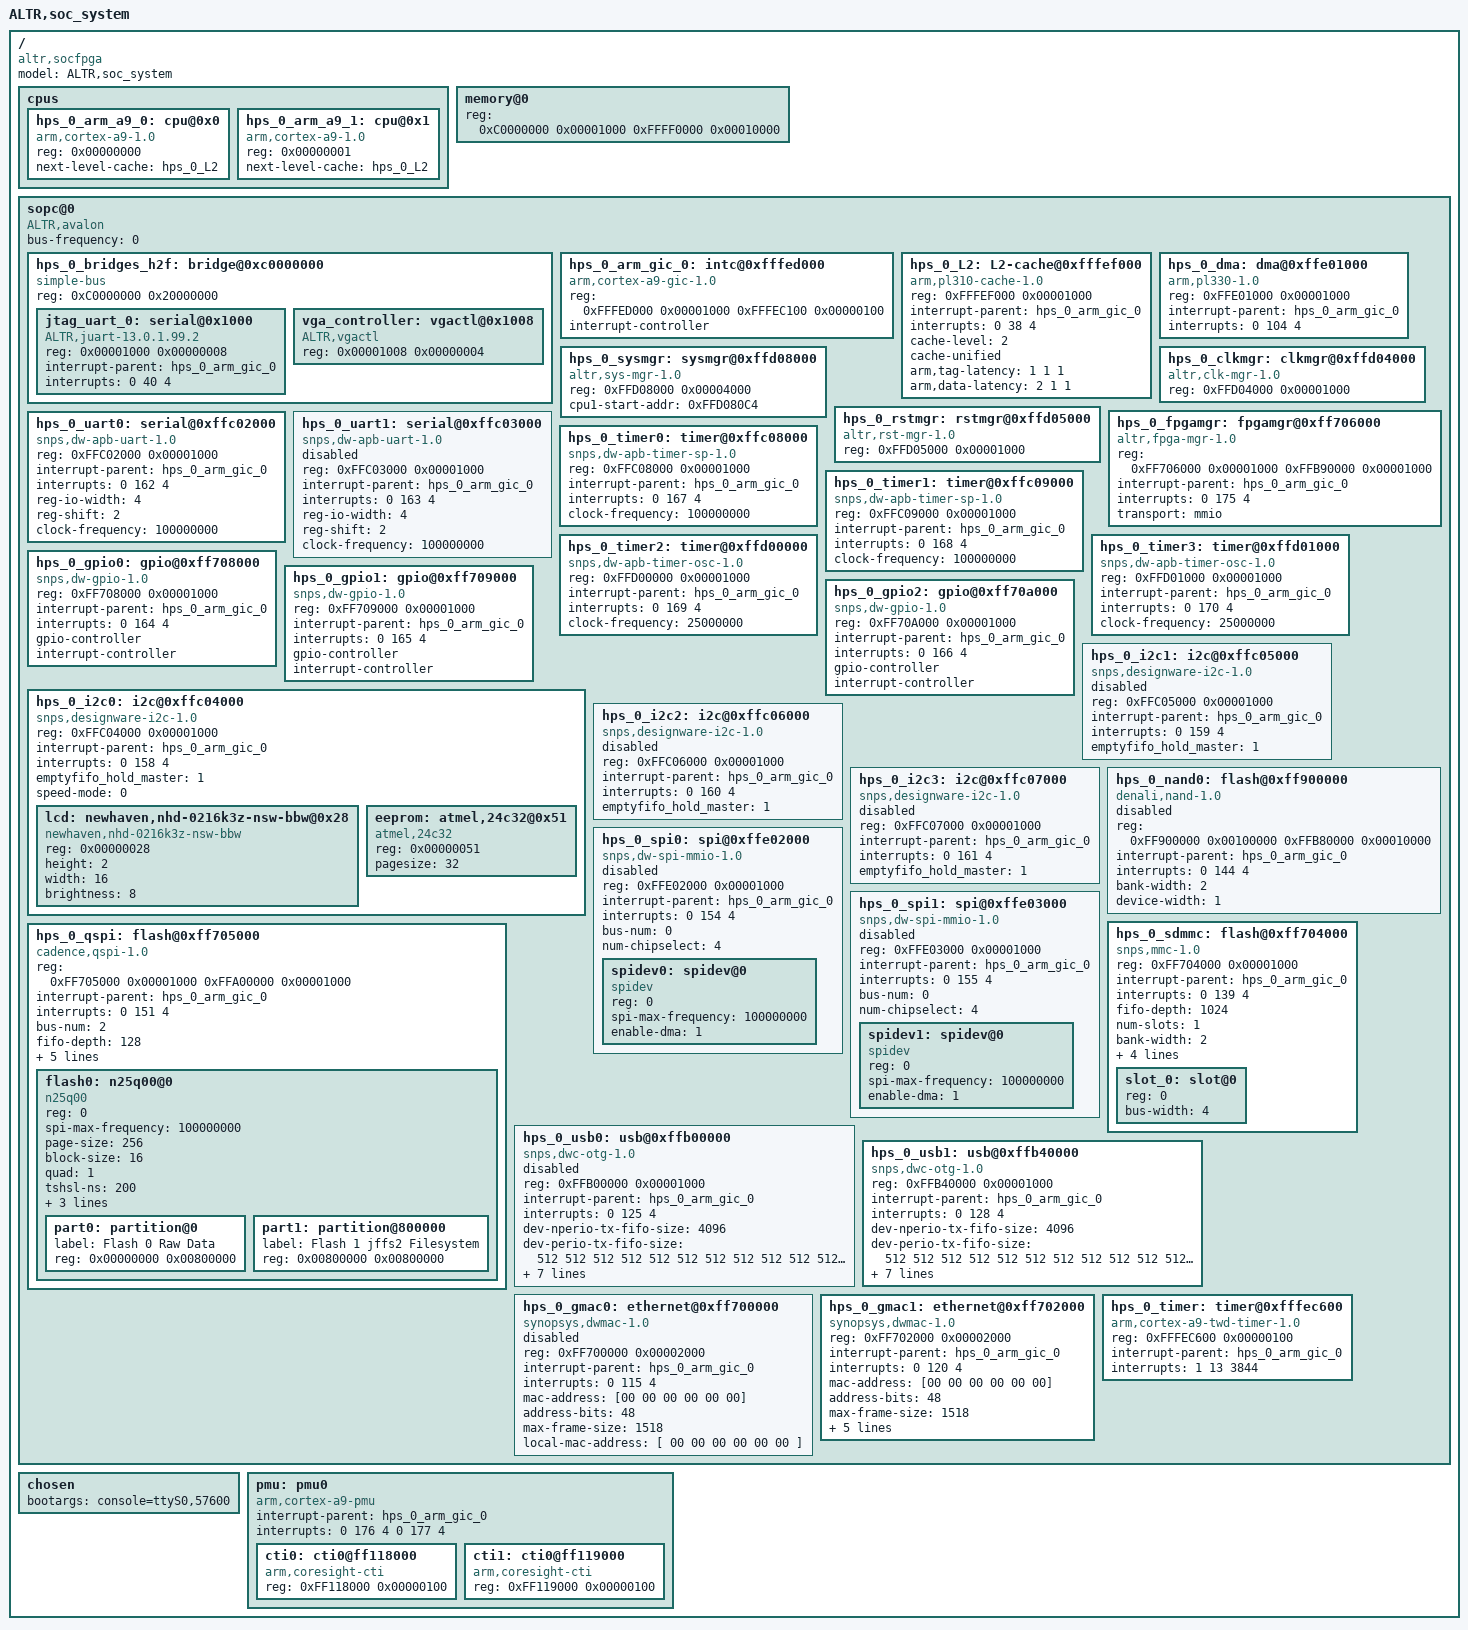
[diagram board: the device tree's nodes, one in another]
/*
 * This devicetree is generated by sopc2dts on Thu Dec 05 01:38:15 EST 2013
 * Sopc2dts is written by Walter Goossens <waltergoossens@home.nl>
 * in cooperation with the nios2 community <Nios2-dev@sopc.et.ntust.edu.tw>
 */
/dts-v1/;

/ {
	model = "ALTR,soc_system";
	#address-cells = < 1 >;
	#size-cells = < 1 >;
	compatible = "altr,socfpga";

	cpus {
		#address-cells = < 1 >;
		#size-cells = < 0 >;

		hps_0_arm_a9_0: cpu@0x0 {
			device_type = "cpu";
			compatible = "arm,cortex-a9-1.0", "arm,cortex-a9";
			reg = < 0x00000000 >;
			next-level-cache = < &hps_0_L2 >;	/* appended from boardinfo */
		}; //end cpu@0x0 (hps_0_arm_a9_0)

		hps_0_arm_a9_1: cpu@0x1 {
			device_type = "cpu";
			compatible = "arm,cortex-a9-1.0", "arm,cortex-a9";
			reg = < 0x00000001 >;
			next-level-cache = < &hps_0_L2 >;	/* appended from boardinfo */
		}; //end cpu@0x1 (hps_0_arm_a9_1)
	}; //end cpus

	memory@0 {
		device_type = "memory";
		reg = < 0xC0000000 0x00001000 
			0xFFFF0000 0x00010000 >;
	}; //end memory@0

	sopc@0 {
		device_type = "soc";
		ranges;
		#address-cells = < 1 >;
		#size-cells = < 1 >;
		compatible = "ALTR,avalon", "simple-bus";
		bus-frequency = < 0 >;

		hps_0_bridges_h2f: bridge@0xc0000000 {
			reg = < 0xC0000000 0x20000000 >;
			#address-cells = < 1 >;
			#size-cells = < 1 >;
			ranges = < 0x00000000 0xC0000000 0x00001000 
				0x00001000 0xC0001000 0x00000008 
				0x00001008 0xC0001008 0x00000004 >;
			compatible = "simple-bus";	/* appended from boardinfo */

			jtag_uart_0: serial@0x1000 {
				compatible = "ALTR,juart-13.0.1.99.2", "ALTR,juart-1.0";
				reg = < 0x00001000 0x00000008 >;
				interrupt-parent = < &hps_0_arm_gic_0 >;
				interrupts = < 0 40 4 >;
			}; //end serial@0x1000 (jtag_uart_0)

			vga_controller: vgactl@0x1008 {
				compatible = "ALTR,vgactl", "altr,vgactl";
				reg = < 0x00001008 0x00000004 >;
			}; //end vgactl@0x1008 (vga_controller)
		}; //end bridge@0xc0000000 (hps_0_bridges_h2f)

		hps_0_arm_gic_0: intc@0xfffed000 {
			compatible = "arm,cortex-a9-gic-1.0", "arm,cortex-a9-gic";
			reg = < 0xFFFED000 0x00001000 
				0xFFFEC100 0x00000100 >;
			interrupt-controller;
			#interrupt-cells = < 3 >;
		}; //end intc@0xfffed000 (hps_0_arm_gic_0)

		hps_0_L2: L2-cache@0xfffef000 {
			compatible = "arm,pl310-cache-1.0", "arm,pl310-cache";
			reg = < 0xFFFEF000 0x00001000 >;
			interrupt-parent = < &hps_0_arm_gic_0 >;
			interrupts = < 0 38 4 >;
			cache-level = < 2 >;	/* embeddedsw.dts.params.cache-level type NUMBER */
			cache-unified;	/* appended from boardinfo */
			arm,tag-latency = < 1 1 1 >;	/* appended from boardinfo */
			arm,data-latency = < 2 1 1 >;	/* appended from boardinfo */
		}; //end L2-cache@0xfffef000 (hps_0_L2)

		hps_0_dma: dma@0xffe01000 {
			compatible = "arm,pl330-1.0", "arm,pl330", "arm,primecell";
			reg = < 0xFFE01000 0x00001000 >;
			interrupt-parent = < &hps_0_arm_gic_0 >;
			interrupts = < 0 104 4 >;
		}; //end dma@0xffe01000 (hps_0_dma)

		hps_0_sysmgr: sysmgr@0xffd08000 {
			compatible = "altr,sys-mgr-1.0", "altr,sys-mgr";
			reg = < 0xFFD08000 0x00004000 >;
			cpu1-start-addr = < 0xFFD080C4 >;	/* appended from boardinfo */
		}; //end sysmgr@0xffd08000 (hps_0_sysmgr)

		hps_0_clkmgr: clkmgr@0xffd04000 {
			compatible = "altr,clk-mgr-1.0", "altr,clk-mgr";
			reg = < 0xFFD04000 0x00001000 >;
		}; //end clkmgr@0xffd04000 (hps_0_clkmgr)

		hps_0_rstmgr: rstmgr@0xffd05000 {
			compatible = "altr,rst-mgr-1.0", "altr,rst-mgr";
			reg = < 0xFFD05000 0x00001000 >;
		}; //end rstmgr@0xffd05000 (hps_0_rstmgr)

		hps_0_fpgamgr: fpgamgr@0xff706000 {
			compatible = "altr,fpga-mgr-1.0", "altr,fpga-mgr";
			reg = < 0xFF706000 0x00001000 
				0xFFB90000 0x00001000 >;
			interrupt-parent = < &hps_0_arm_gic_0 >;
			interrupts = < 0 175 4 >;
			transport = "mmio";	/* embeddedsw.dts.params.transport type STRING */
		}; //end fpgamgr@0xff706000 (hps_0_fpgamgr)

		hps_0_uart0: serial@0xffc02000 {
			compatible = "snps,dw-apb-uart-1.0", "snps,dw-apb-uart";
			reg = < 0xFFC02000 0x00001000 >;
			interrupt-parent = < &hps_0_arm_gic_0 >;
			interrupts = < 0 162 4 >;
			reg-io-width = < 4 >;	/* embeddedsw.dts.params.reg-io-width type NUMBER */
			reg-shift = < 2 >;	/* embeddedsw.dts.params.reg-shift type NUMBER */
			clock-frequency = < 100000000 >;	/* appended from boardinfo */
		}; //end serial@0xffc02000 (hps_0_uart0)

		hps_0_uart1: serial@0xffc03000 {
			compatible = "snps,dw-apb-uart-1.0", "snps,dw-apb-uart";
			reg = < 0xFFC03000 0x00001000 >;
			interrupt-parent = < &hps_0_arm_gic_0 >;
			interrupts = < 0 163 4 >;
			reg-io-width = < 4 >;	/* embeddedsw.dts.params.reg-io-width type NUMBER */
			reg-shift = < 2 >;	/* embeddedsw.dts.params.reg-shift type NUMBER */
			clock-frequency = < 100000000 >;	/* appended from boardinfo */
			status = "disabled";	/* appended from boardinfo */
		}; //end serial@0xffc03000 (hps_0_uart1)

		hps_0_timer0: timer@0xffc08000 {
			compatible = "snps,dw-apb-timer-sp-1.0", "snps,dw-apb-timer-sp";
			reg = < 0xFFC08000 0x00001000 >;
			interrupt-parent = < &hps_0_arm_gic_0 >;
			interrupts = < 0 167 4 >;
			clock-frequency = < 100000000 >;	/* appended from boardinfo */
		}; //end timer@0xffc08000 (hps_0_timer0)

		hps_0_timer1: timer@0xffc09000 {
			compatible = "snps,dw-apb-timer-sp-1.0", "snps,dw-apb-timer-sp";
			reg = < 0xFFC09000 0x00001000 >;
			interrupt-parent = < &hps_0_arm_gic_0 >;
			interrupts = < 0 168 4 >;
			clock-frequency = < 100000000 >;	/* appended from boardinfo */
		}; //end timer@0xffc09000 (hps_0_timer1)

		hps_0_timer2: timer@0xffd00000 {
			compatible = "snps,dw-apb-timer-osc-1.0", "snps,dw-apb-timer-osc";
			reg = < 0xFFD00000 0x00001000 >;
			interrupt-parent = < &hps_0_arm_gic_0 >;
			interrupts = < 0 169 4 >;
			clock-frequency = < 25000000 >;	/* appended from boardinfo */
		}; //end timer@0xffd00000 (hps_0_timer2)

		hps_0_timer3: timer@0xffd01000 {
			compatible = "snps,dw-apb-timer-osc-1.0", "snps,dw-apb-timer-osc";
			reg = < 0xFFD01000 0x00001000 >;
			interrupt-parent = < &hps_0_arm_gic_0 >;
			interrupts = < 0 170 4 >;
			clock-frequency = < 25000000 >;	/* appended from boardinfo */
		}; //end timer@0xffd01000 (hps_0_timer3)

		hps_0_gpio0: gpio@0xff708000 {
			compatible = "snps,dw-gpio-1.0", "snps,dw-gpio";
			reg = < 0xFF708000 0x00001000 >;
			interrupt-parent = < &hps_0_arm_gic_0 >;
			interrupts = < 0 164 4 >;
			#gpio-cells = < 2 >;
			gpio-controller;
			interrupt-controller;	/* appended from boardinfo */
			#interrupt-cells = < 2 >;	/* appended from boardinfo */
		}; //end gpio@0xff708000 (hps_0_gpio0)

		hps_0_gpio1: gpio@0xff709000 {
			compatible = "snps,dw-gpio-1.0", "snps,dw-gpio";
			reg = < 0xFF709000 0x00001000 >;
			interrupt-parent = < &hps_0_arm_gic_0 >;
			interrupts = < 0 165 4 >;
			#gpio-cells = < 2 >;
			gpio-controller;
			interrupt-controller;	/* appended from boardinfo */
			#interrupt-cells = < 2 >;	/* appended from boardinfo */
		}; //end gpio@0xff709000 (hps_0_gpio1)

		hps_0_gpio2: gpio@0xff70a000 {
			compatible = "snps,dw-gpio-1.0", "snps,dw-gpio";
			reg = < 0xFF70A000 0x00001000 >;
			interrupt-parent = < &hps_0_arm_gic_0 >;
			interrupts = < 0 166 4 >;
			#gpio-cells = < 2 >;
			gpio-controller;
			interrupt-controller;	/* appended from boardinfo */
			#interrupt-cells = < 2 >;	/* appended from boardinfo */
		}; //end gpio@0xff70a000 (hps_0_gpio2)

		hps_0_i2c0: i2c@0xffc04000 {
			compatible = "snps,designware-i2c-1.0", "snps,designware-i2c";
			reg = < 0xFFC04000 0x00001000 >;
			interrupt-parent = < &hps_0_arm_gic_0 >;
			interrupts = < 0 158 4 >;
			emptyfifo_hold_master = < 1 >;	/* embeddedsw.dts.params.emptyfifo_hold_master type NUMBER */
			#address-cells = < 1 >;
			#size-cells = < 0 >;
			speed-mode = < 0 >;	/* appended from boardinfo */

			lcd: newhaven,nhd-0216k3z-nsw-bbw@0x28 {
				compatible = "newhaven,nhd-0216k3z-nsw-bbw";
				reg = < 0x00000028 >;
				height = < 2 >;	/* appended from boardinfo */
				width = < 16 >;	/* appended from boardinfo */
				brightness = < 8 >;	/* appended from boardinfo */
			}; //end newhaven,nhd-0216k3z-nsw-bbw@0x28 (lcd)

			eeprom: atmel,24c32@0x51 {
				compatible = "atmel,24c32";
				reg = < 0x00000051 >;
				pagesize = < 32 >;	/* appended from boardinfo */
			}; //end atmel,24c32@0x51 (eeprom)
		}; //end i2c@0xffc04000 (hps_0_i2c0)

		hps_0_i2c1: i2c@0xffc05000 {
			compatible = "snps,designware-i2c-1.0", "snps,designware-i2c";
			reg = < 0xFFC05000 0x00001000 >;
			interrupt-parent = < &hps_0_arm_gic_0 >;
			interrupts = < 0 159 4 >;
			emptyfifo_hold_master = < 1 >;	/* embeddedsw.dts.params.emptyfifo_hold_master type NUMBER */
			status = "disabled";	/* appended from boardinfo */
		}; //end i2c@0xffc05000 (hps_0_i2c1)

		hps_0_i2c2: i2c@0xffc06000 {
			compatible = "snps,designware-i2c-1.0", "snps,designware-i2c";
			reg = < 0xFFC06000 0x00001000 >;
			interrupt-parent = < &hps_0_arm_gic_0 >;
			interrupts = < 0 160 4 >;
			emptyfifo_hold_master = < 1 >;	/* embeddedsw.dts.params.emptyfifo_hold_master type NUMBER */
			status = "disabled";	/* appended from boardinfo */
		}; //end i2c@0xffc06000 (hps_0_i2c2)

		hps_0_i2c3: i2c@0xffc07000 {
			compatible = "snps,designware-i2c-1.0", "snps,designware-i2c";
			reg = < 0xFFC07000 0x00001000 >;
			interrupt-parent = < &hps_0_arm_gic_0 >;
			interrupts = < 0 161 4 >;
			emptyfifo_hold_master = < 1 >;	/* embeddedsw.dts.params.emptyfifo_hold_master type NUMBER */
			status = "disabled";	/* appended from boardinfo */
		}; //end i2c@0xffc07000 (hps_0_i2c3)

		hps_0_nand0: flash@0xff900000 {
			compatible = "denali,nand-1.0", "denali,denali-nand-dt";
			reg = < 0xFF900000 0x00100000 
				0xFFB80000 0x00010000 >;
			interrupt-parent = < &hps_0_arm_gic_0 >;
			interrupts = < 0 144 4 >;
			#adress-cells = < 1 >;	/* embeddedsw.dts.params.#adress-cells type NUMBER */
			#size-cells = < 1 >;	/* embeddedsw.dts.params.#size-cells type NUMBER */
			reg-names = "nand_data", "denali_reg";	/* embeddedsw.dts.params.reg-names type STRING */
			bank-width = < 2 >;
			device-width = < 1 >;
			status = "disabled";	/* appended from boardinfo */
		}; //end flash@0xff900000 (hps_0_nand0)

		hps_0_spi0: spi@0xffe02000 {
			compatible = "snps,dw-spi-mmio-1.0", "snps,dw-spi-mmio";
			reg = < 0xFFE02000 0x00001000 >;
			interrupt-parent = < &hps_0_arm_gic_0 >;
			interrupts = < 0 154 4 >;
			#address-cells = < 1 >;	/* embeddedsw.dts.params.#address-cells type NUMBER */
			#size-cells = < 0 >;	/* embeddedsw.dts.params.#size-cells type NUMBER */
			bus-num = < 0 >;	/* embeddedsw.dts.params.bus-num type NUMBER */
			num-chipselect = < 4 >;	/* embeddedsw.dts.params.num-chipselect type NUMBER */
			status = "disabled";	/* appended from boardinfo */

			spidev0: spidev@0 {
				compatible = "spidev";	/* appended from boardinfo */
				reg = < 0 >;	/* appended from boardinfo */
				spi-max-frequency = < 100000000 >;	/* appended from boardinfo */
				enable-dma = < 1 >;	/* appended from boardinfo */
			}; //end spidev@0 (spidev0)
		}; //end spi@0xffe02000 (hps_0_spi0)

		hps_0_spi1: spi@0xffe03000 {
			compatible = "snps,dw-spi-mmio-1.0", "snps,dw-spi-mmio";
			reg = < 0xFFE03000 0x00001000 >;
			interrupt-parent = < &hps_0_arm_gic_0 >;
			interrupts = < 0 155 4 >;
			#address-cells = < 1 >;	/* embeddedsw.dts.params.#address-cells type NUMBER */
			#size-cells = < 0 >;	/* embeddedsw.dts.params.#size-cells type NUMBER */
			bus-num = < 0 >;	/* embeddedsw.dts.params.bus-num type NUMBER */
			num-chipselect = < 4 >;	/* embeddedsw.dts.params.num-chipselect type NUMBER */
			status = "disabled";	/* appended from boardinfo */

			spidev1: spidev@0 {
				compatible = "spidev";	/* appended from boardinfo */
				reg = < 0 >;	/* appended from boardinfo */
				spi-max-frequency = < 100000000 >;	/* appended from boardinfo */
				enable-dma = < 1 >;	/* appended from boardinfo */
			}; //end spidev@0 (spidev1)
		}; //end spi@0xffe03000 (hps_0_spi1)

		hps_0_qspi: flash@0xff705000 {
			compatible = "cadence,qspi-1.0", "cadence,qspi";
			reg = < 0xFF705000 0x00001000 
				0xFFA00000 0x00001000 >;
			interrupt-parent = < &hps_0_arm_gic_0 >;
			interrupts = < 0 151 4 >;
			bus-num = < 2 >;	/* embeddedsw.dts.params.bus-num type NUMBER */
			fifo-depth = < 128 >;	/* embeddedsw.dts.params.fifo-depth type NUMBER */
			num-chipselect = < 4 >;	/* embeddedsw.dts.params.num-chipselect type NUMBER */
			bank-width = < 2 >;
			device-width = < 1 >;
			master-ref-clk = < 400000000 >;	/* appended from boardinfo */
			ext-decoder = < 0 >;	/* appended from boardinfo */
			#address-cells = < 1 >;	/* appended from boardinfo */
			#size-cells = < 0 >;	/* appended from boardinfo */

			flash0: n25q00@0 {
				#address-cells = < 1 >;	/* appended from boardinfo */
				#size-cells = < 1 >;	/* appended from boardinfo */
				compatible = "n25q00";	/* appended from boardinfo */
				reg = < 0 >;	/* appended from boardinfo */
				spi-max-frequency = < 100000000 >;	/* appended from boardinfo */
				page-size = < 256 >;	/* appended from boardinfo */
				block-size = < 16 >;	/* appended from boardinfo */
				quad = < 1 >;	/* appended from boardinfo */
				tshsl-ns = < 200 >;	/* appended from boardinfo */
				tsd2d-ns = < 255 >;	/* appended from boardinfo */
				tchsh-ns = < 20 >;	/* appended from boardinfo */
				tslch-ns = < 20 >;	/* appended from boardinfo */

				part0: partition@0 {
					label = "Flash 0 Raw Data";	/* appended from boardinfo */
					reg = < 0x00000000 0x00800000 >;	/* appended from boardinfo */
				}; //end partition@0 (part0)

				part1: partition@800000 {
					label = "Flash 1 jffs2 Filesystem";	/* appended from boardinfo */
					reg = < 0x00800000 0x00800000 >;	/* appended from boardinfo */
				}; //end partition@800000 (part1)
			}; //end n25q00@0 (flash0)
		}; //end flash@0xff705000 (hps_0_qspi)

		hps_0_sdmmc: flash@0xff704000 {
			compatible = "snps,mmc-1.0", "snps,dw-mshc";
			reg = < 0xFF704000 0x00001000 >;
			interrupt-parent = < &hps_0_arm_gic_0 >;
			interrupts = < 0 139 4 >;
			fifo-depth = < 1024 >;	/* embeddedsw.dts.params.fifo-depth type NUMBER */
			num-slots = < 1 >;	/* embeddedsw.dts.params.num-slots type NUMBER */
			bank-width = < 2 >;
			device-width = < 1 >;
			bus-hz = < 12500000 >;	/* appended from boardinfo */
			#address-cells = < 1 >;	/* appended from boardinfo */
			#size-cells = < 0 >;	/* appended from boardinfo */
			supports-highspeed;	/* appended from boardinfo */
			broken-cd;	/* appended from boardinfo */

			slot_0: slot@0 {
				reg = < 0 >;	/* appended from boardinfo */
				bus-width = < 4 >;	/* appended from boardinfo */
			}; //end slot@0 (slot_0)
		}; //end flash@0xff704000 (hps_0_sdmmc)

		hps_0_usb0: usb@0xffb00000 {
			compatible = "snps,dwc-otg-1.0", "snps,dwc-otg";
			reg = < 0xFFB00000 0x00001000 >;
			interrupt-parent = < &hps_0_arm_gic_0 >;
			interrupts = < 0 125 4 >;
			dev-nperio-tx-fifo-size = < 4096 >;	/* embeddedsw.dts.params.dev-nperio-tx-fifo-size type NUMBER */
			dev-perio-tx-fifo-size = "<512 512 512 512 512 512 512 512 512 512 512 512 512 512 512>";	/* embeddedsw.dts.params.dev-perio-tx-fifo-size type STRING */
			dev-tx-fifo-size = "<512 512 512 512 512 512 512 512 512 512 512 512 512 512 512>";	/* embeddedsw.dts.params.dev-tx-fifo-size type STRING */
			dev_rx_fifo-size = < 512 >;	/* embeddedsw.dts.params.dev_rx_fifo-size type NUMBER */
			dma-mask = < 268435455 >;	/* embeddedsw.dts.params.dma-mask type NUMBER */
			host_rx_fifo-size = < 512 >;	/* embeddedsw.dts.params.host_rx_fifo-size type NUMBER */
			ulpi-ddr = < 0 >;	/* embeddedsw.dts.params.ulpi-ddr type NUMBER */
			voltage-switch = < 0 >;	/* embeddedsw.dts.params.voltage-switch type NUMBER */
			status = "disabled";	/* appended from boardinfo */
		}; //end usb@0xffb00000 (hps_0_usb0)

		hps_0_usb1: usb@0xffb40000 {
			compatible = "snps,dwc-otg-1.0", "snps,dwc-otg";
			reg = < 0xFFB40000 0x00001000 >;
			interrupt-parent = < &hps_0_arm_gic_0 >;
			interrupts = < 0 128 4 >;
			dev-nperio-tx-fifo-size = < 4096 >;	/* embeddedsw.dts.params.dev-nperio-tx-fifo-size type NUMBER */
			dev-perio-tx-fifo-size = "<512 512 512 512 512 512 512 512 512 512 512 512 512 512 512>";	/* embeddedsw.dts.params.dev-perio-tx-fifo-size type STRING */
			dev-tx-fifo-size = "<512 512 512 512 512 512 512 512 512 512 512 512 512 512 512>";	/* embeddedsw.dts.params.dev-tx-fifo-size type STRING */
			dev_rx_fifo-size = < 512 >;	/* embeddedsw.dts.params.dev_rx_fifo-size type NUMBER */
			dma-mask = < 268435455 >;	/* embeddedsw.dts.params.dma-mask type NUMBER */
			host_rx_fifo-size = < 512 >;	/* embeddedsw.dts.params.host_rx_fifo-size type NUMBER */
			ulpi-ddr = < 0 >;	/* embeddedsw.dts.params.ulpi-ddr type NUMBER */
			voltage-switch = < 0 >;	/* embeddedsw.dts.params.voltage-switch type NUMBER */
		}; //end usb@0xffb40000 (hps_0_usb1)

		hps_0_gmac0: ethernet@0xff700000 {
			compatible = "synopsys,dwmac-1.0", "altr,socfpga-stmmac", "snps,dwmac-3.70a", "snps,dwmac";
			reg = < 0xFF700000 0x00002000 >;
			interrupt-parent = < &hps_0_arm_gic_0 >;
			interrupts = < 0 115 4 >;
			interrupt-names = "macirq";	/* embeddedsw.dts.params.interrupt-names type STRING */
			mac-address = "[00 00 00 00 00 00]";	/* embeddedsw.dts.params.mac-address type STRING */
			address-bits = < 48 >;
			max-frame-size = < 1518 >;
			local-mac-address = [ 00 00 00 00 00 00 ];
			status = "disabled";	/* appended from boardinfo */
		}; //end ethernet@0xff700000 (hps_0_gmac0)

		hps_0_gmac1: ethernet@0xff702000 {
			compatible = "synopsys,dwmac-1.0", "altr,socfpga-stmmac", "snps,dwmac-3.70a", "snps,dwmac";
			reg = < 0xFF702000 0x00002000 >;
			interrupt-parent = < &hps_0_arm_gic_0 >;
			interrupts = < 0 120 4 >;
			interrupt-names = "macirq";	/* embeddedsw.dts.params.interrupt-names type STRING */
			mac-address = "[00 00 00 00 00 00]";	/* embeddedsw.dts.params.mac-address type STRING */
			address-bits = < 48 >;
			max-frame-size = < 1518 >;
			local-mac-address = [ 00 00 00 00 00 00 ];
			phy-mode = "rgmii";	/* appended from boardinfo */
			phy-addr = < 0xFFFFFFFF >;	/* appended from boardinfo */
			micrel-ksz9021rlrn-clk-skew = < 0x0000A0E0 >;	/* appended from boardinfo */
			micrel-ksz9021rlrn-rx-skew = < 0x00000000 >;	/* appended from boardinfo */
		}; //end ethernet@0xff702000 (hps_0_gmac1)

		hps_0_timer: timer@0xfffec600 {
			compatible = "arm,cortex-a9-twd-timer-1.0", "arm,cortex-a9-twd-timer";
			reg = < 0xFFFEC600 0x00000100 >;
			interrupt-parent = < &hps_0_arm_gic_0 >;
			interrupts = < 1 13 3844 >;
		}; //end timer@0xfffec600 (hps_0_timer)
	}; //end sopc@0

	chosen {
		bootargs = "console=ttyS0,57600";
	}; //end chosen


	pmu: pmu0 {
		#address-cells = < 1 >;	/* appended from boardinfo */
		#size-cells = < 1 >;	/* appended from boardinfo */
		compatible = "arm,cortex-a9-pmu";	/* appended from boardinfo */
		interrupt-parent = < &hps_0_arm_gic_0 >;	/* appended from boardinfo */
		interrupts = < 0 176 4 0 177 4 >;	/* appended from boardinfo */
		ranges;	/* appended from boardinfo */

		cti0: cti0@ff118000 {
			compatible = "arm,coresight-cti";	/* appended from boardinfo */
			reg = < 0xFF118000 0x00000100 >;	/* appended from boardinfo */
		}; //end cti0@ff118000 (cti0)

		cti1: cti0@ff119000 {
			compatible = "arm,coresight-cti";	/* appended from boardinfo */
			reg = < 0xFF119000 0x00000100 >;	/* appended from boardinfo */
		}; //end cti0@ff119000 (cti1)
	}; //end pmu0 (pmu)
}; //end /
